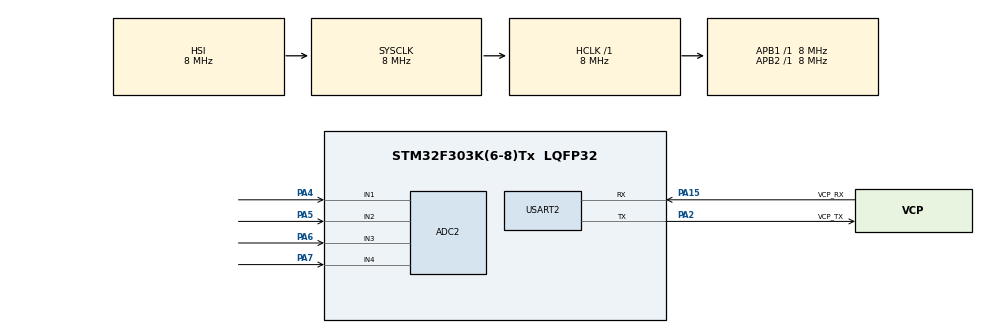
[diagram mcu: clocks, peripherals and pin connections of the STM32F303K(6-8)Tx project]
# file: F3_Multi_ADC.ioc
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ADC2.Channel-0\#ChannelRegularConversion=ADC_CHANNEL_4
ADC2.Channel-1\#ChannelRegularConversion=ADC_CHANNEL_3
ADC2.Channel-2\#ChannelRegularConversion=ADC_CHANNEL_2
ADC2.Channel-3\#ChannelRegularConversion=ADC_CHANNEL_1
ADC2.ClockPrescaler=ADC_CLOCK_SYNC_PCLK_DIV4
ADC2.ContinuousConvMode=ENABLE
ADC2.DMAContinuousRequests=ENABLE
ADC2.EOCSelection=ADC_EOC_SINGLE_CONV
ADC2.NbrOfConversion=4
ADC2.NbrOfConversionFlag=1
ADC2.Offset-0\#ChannelRegularConversion=0
ADC2.Offset-1\#ChannelRegularConversion=0
ADC2.Offset-2\#ChannelRegularConversion=0
ADC2.Offset-3\#ChannelRegularConversion=0
ADC2.OffsetNumber-0\#ChannelRegularConversion=ADC_OFFSET_NONE
ADC2.OffsetNumber-1\#ChannelRegularConversion=ADC_OFFSET_NONE
ADC2.OffsetNumber-2\#ChannelRegularConversion=ADC_OFFSET_NONE
ADC2.OffsetNumber-3\#ChannelRegularConversion=ADC_OFFSET_NONE
ADC2.Rank-0\#ChannelRegularConversion=1
ADC2.Rank-1\#ChannelRegularConversion=2
ADC2.Rank-2\#ChannelRegularConversion=3
ADC2.Rank-3\#ChannelRegularConversion=4
ADC2.SamplingTime-0\#ChannelRegularConversion=ADC_SAMPLETIME_61CYCLES_5
ADC2.SamplingTime-1\#ChannelRegularConversion=ADC_SAMPLETIME_61CYCLES_5
ADC2.SamplingTime-2\#ChannelRegularConversion=ADC_SAMPLETIME_61CYCLES_5
ADC2.SamplingTime-3\#ChannelRegularConversion=ADC_SAMPLETIME_61CYCLES_5
ADC2.SamplingTimeOPAMP-1\#ChannelRegularConversion=ADC_SAMPLETIME_7CYCLES_5
ADC2.SamplingTimeOPAMP-2\#ChannelRegularConversion=ADC_SAMPLETIME_7CYCLES_5
ADC2.SamplingTimeOPAMP-3\#ChannelRegularConversion=ADC_SAMPLETIME_7CYCLES_5
ADC2.SubFamily=STM32F303x8
Dma.ADC2.0.Direction=DMA_PERIPH_TO_MEMORY
Dma.ADC2.0.Instance=DMA1_Channel2
Dma.ADC2.0.MemDataAlignment=DMA_MDATAALIGN_HALFWORD
Dma.ADC2.0.MemInc=DMA_MINC_ENABLE
Dma.ADC2.0.Mode=DMA_CIRCULAR
Dma.ADC2.0.PeriphDataAlignment=DMA_PDATAALIGN_HALFWORD
Dma.ADC2.0.PeriphInc=DMA_PINC_DISABLE
Dma.ADC2.0.Priority=DMA_PRIORITY_LOW
Dma.Request0=ADC2
Mcu.Family=STM32F3
Mcu.Name=STM32F303K(6-8)Tx
Mcu.Package=LQFP32
NVIC.DMA1_Channel2_IRQn=true\:0\:0\:false\:false\:true\:false\:true\:true
NVIC.PriorityGroup=NVIC_PRIORITYGROUP_4
PA13.GPIO_Label=SWDIO
PA13.Mode=Serial_Wire
PA13.Signal=SYS_JTMS-SWDIO
PA14.GPIO_Label=SWCLK
PA14.Mode=Serial_Wire
PA14.Signal=SYS_JTCK-SWCLK
PA15.GPIO_Label=VCP_RX
PA15.Mode=Asynchronous
PA15.Signal=USART2_RX
PA2.GPIO_Label=VCP_TX
PA2.Mode=Asynchronous
PA2.Signal=USART2_TX
PA4.Mode=IN1-Single-Ended
PA4.Signal=ADC2_IN1
PA5.Mode=IN2-Single-Ended
PA5.Signal=ADC2_IN2
PA6.Mode=IN3-Single-Ended
PA6.Signal=ADC2_IN3
PA7.Mode=IN4-Single-Ended
PA7.Signal=ADC2_IN4
PF0\ /\ OSC_IN.GPIO_Label=MCO
PF0\ /\ OSC_IN.Mode=HSE-External-Clock-Source
PF0\ /\ OSC_IN.Signal=RCC_OSC_IN
ProjectManager.HeapSize=0x200
ProjectManager.StackSize=0x400
ProjectManager.TargetToolchain=STM32CubeIDE
RCC.AHBFreq_Value=8000000
RCC.APB1Freq_Value=8000000
RCC.APB2Freq_Value=8000000
RCC.CortexFreq_Value=8000000
RCC.HSE_VALUE=8000000
RCC.HSI_VALUE=8000000
RCC.PLLMUL=RCC_PLL_MUL4
RCC.SYSCLKFreq_VALUE=8000000
USART2.VirtualMode-Asynchronous=VM_ASYNC
board=NUCLEO-F303K8

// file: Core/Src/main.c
/* USER CODE BEGIN Header */
/**
  ******************************************************************************
  * @file           : main.c
  * @brief          : Main program body
  ******************************************************************************
  * @attention
  *
  * Copyright (c) 2024 STMicroelectronics.
  * All rights reserved.
  *
  * This software is licensed under terms that can be found in the LICENSE file
  * in the root directory of this software component.
  * If no LICENSE file comes with this software, it is provided AS-IS.
  *
  ******************************************************************************
  */
/* USER CODE END Header */
#include "main.h"

/* USER CODE BEGIN PD */
uint16_t adcvalue[4];
/* USER CODE END PD */

ADC_HandleTypeDef hadc2;
DMA_HandleTypeDef hdma_adc2;

UART_HandleTypeDef huart2;

void SystemClock_Config(void);
static void MX_GPIO_Init(void);
static void MX_DMA_Init(void);
static void MX_USART2_UART_Init(void);
static void MX_ADC2_Init(void);

int main(void)
{

  /* MCU Configuration--------------------------------------------------------*/

  /* Reset of all peripherals, Initializes the Flash interface and the Systick. */
  HAL_Init();

  /* Configure the system clock */
  SystemClock_Config();

  /* Initialize all configured peripherals */
  MX_GPIO_Init();
  MX_DMA_Init();
  MX_USART2_UART_Init();
  MX_ADC2_Init();
  /* USER CODE BEGIN 2 */
HAL_ADCEx_Calibration_Start(&hadc2,ADC_SINGLE_ENDED);

uint16_t result[16] = {0};

HAL_ADC_Start_DMA(&hadc2,(uint32_t *)&result,4);

//HAL_ADC_PollForConversion(&hadc2,HAL_MAX_DELAY);

//HAL_ADC_Start(&hadc2);

//while(!(ADC2->ISR & (1<<2))){}
//result[0]=HAL_ADC_GetValue(&hadc2);
//
//while(!(ADC2->ISR & (1<<2))){}
//result[1]=HAL_ADC_GetValue(&hadc2);
//
//while(!(ADC2->ISR & (1<<2))){}
//result[2]=HAL_ADC_GetValue(&hadc2);
//
//while(!(ADC2->ISR & (1<<2))){}
//result[3]=HAL_ADC_GetValue(&hadc2);
//
//HAL_ADC_Start(&hadc2);
//
//while(!(ADC2->ISR & (1<<2))){}
//result[4]=HAL_ADC_GetValue(&hadc2);
//
//while(!(ADC2->ISR & (1<<2))){}
//result[5]=HAL_ADC_GetValue(&hadc2);
//
//while(!(ADC2->ISR & (1<<2))){}
//result[6]=HAL_ADC_GetValue(&hadc2);
//
//while(!(ADC2->ISR & (1<<2))){}
//result[7]=HAL_ADC_GetValue(&hadc2);
  /* USER CODE END 2 */

  /* Infinite loop */
  /* USER CODE BEGIN WHILE */
  while (1)
  {
	  for(int i=0;i<8;i++){
		  adcvalue[i]=result[i];
	  }
//	  HAL_Delay(100);
    /* USER CODE END WHILE */

  }
}

void SystemClock_Config(void)
{
  RCC_OscInitTypeDef RCC_OscInitStruct = {0};
  RCC_ClkInitTypeDef RCC_ClkInitStruct = {0};

  /** Initializes the RCC Oscillators according to the specified parameters
  * in the RCC_OscInitTypeDef structure.
  */
  RCC_OscInitStruct.OscillatorType = RCC_OSCILLATORTYPE_HSI;
  RCC_OscInitStruct.HSIState = RCC_HSI_ON;
  RCC_OscInitStruct.HSICalibrationValue = RCC_HSICALIBRATION_DEFAULT;
  RCC_OscInitStruct.PLL.PLLState = RCC_PLL_NONE;
  if (HAL_RCC_OscConfig(&RCC_OscInitStruct) != HAL_OK)
  {
    Error_Handler();
  }

  /** Initializes the CPU, AHB and APB buses clocks
  */
  RCC_ClkInitStruct.ClockType = RCC_CLOCKTYPE_HCLK|RCC_CLOCKTYPE_SYSCLK
                              |RCC_CLOCKTYPE_PCLK1|RCC_CLOCKTYPE_PCLK2;
  RCC_ClkInitStruct.SYSCLKSource = RCC_SYSCLKSOURCE_HSI;
  RCC_ClkInitStruct.AHBCLKDivider = RCC_SYSCLK_DIV1;
  RCC_ClkInitStruct.APB1CLKDivider = RCC_HCLK_DIV1;
  RCC_ClkInitStruct.APB2CLKDivider = RCC_HCLK_DIV1;

  if (HAL_RCC_ClockConfig(&RCC_ClkInitStruct, FLASH_LATENCY_0) != HAL_OK)
  {
    Error_Handler();
  }
}

static void MX_ADC2_Init(void)
{

  ADC_ChannelConfTypeDef sConfig = {0};

  /** Common config
  */
  hadc2.Instance = ADC2;
  hadc2.Init.ClockPrescaler = ADC_CLOCK_SYNC_PCLK_DIV4;
  hadc2.Init.Resolution = ADC_RESOLUTION_12B;
  hadc2.Init.ScanConvMode = ADC_SCAN_ENABLE;
  hadc2.Init.ContinuousConvMode = ENABLE;
  hadc2.Init.DiscontinuousConvMode = DISABLE;
  hadc2.Init.ExternalTrigConvEdge = ADC_EXTERNALTRIGCONVEDGE_NONE;
  hadc2.Init.ExternalTrigConv = ADC_SOFTWARE_START;
  hadc2.Init.DataAlign = ADC_DATAALIGN_RIGHT;
  hadc2.Init.NbrOfConversion = 4;
  hadc2.Init.DMAContinuousRequests = ENABLE;
  hadc2.Init.EOCSelection = ADC_EOC_SINGLE_CONV;
  hadc2.Init.LowPowerAutoWait = DISABLE;
  hadc2.Init.Overrun = ADC_OVR_DATA_OVERWRITTEN;
  if (HAL_ADC_Init(&hadc2) != HAL_OK)
  {
    Error_Handler();
  }

  /** Configure Regular Channel
  */
  sConfig.Channel = ADC_CHANNEL_4;
  sConfig.Rank = ADC_REGULAR_RANK_1;
  sConfig.SingleDiff = ADC_SINGLE_ENDED;
  sConfig.SamplingTime = ADC_SAMPLETIME_61CYCLES_5;
  sConfig.OffsetNumber = ADC_OFFSET_NONE;
  sConfig.Offset = 0;
  if (HAL_ADC_ConfigChannel(&hadc2, &sConfig) != HAL_OK)
  {
    Error_Handler();
  }

  /** Configure Regular Channel
  */
  sConfig.Channel = ADC_CHANNEL_3;
  sConfig.Rank = ADC_REGULAR_RANK_2;
  if (HAL_ADC_ConfigChannel(&hadc2, &sConfig) != HAL_OK)
  {
    Error_Handler();
  }

  /** Configure Regular Channel
  */
  sConfig.Channel = ADC_CHANNEL_2;
  sConfig.Rank = ADC_REGULAR_RANK_3;
  if (HAL_ADC_ConfigChannel(&hadc2, &sConfig) != HAL_OK)
  {
    Error_Handler();
  }

  /** Configure Regular Channel
  */
  sConfig.Channel = ADC_CHANNEL_1;
  sConfig.Rank = ADC_REGULAR_RANK_4;
  if (HAL_ADC_ConfigChannel(&hadc2, &sConfig) != HAL_OK)
  {
    Error_Handler();
  }

}

static void MX_USART2_UART_Init(void)
{

  huart2.Instance = USART2;
  huart2.Init.BaudRate = 38400;
  huart2.Init.WordLength = UART_WORDLENGTH_8B;
  huart2.Init.StopBits = UART_STOPBITS_1;
  huart2.Init.Parity = UART_PARITY_NONE;
  huart2.Init.Mode = UART_MODE_TX_RX;
  huart2.Init.HwFlowCtl = UART_HWCONTROL_NONE;
  huart2.Init.OverSampling = UART_OVERSAMPLING_16;
  huart2.Init.OneBitSampling = UART_ONE_BIT_SAMPLE_DISABLE;
  huart2.AdvancedInit.AdvFeatureInit = UART_ADVFEATURE_NO_INIT;
  if (HAL_UART_Init(&huart2) != HAL_OK)
  {
    Error_Handler();
  }

}

static void MX_DMA_Init(void)
{

  /* DMA controller clock enable */
  __HAL_RCC_DMA1_CLK_ENABLE();

  /* DMA interrupt init */
  /* DMA1_Channel2_IRQn interrupt configuration */
  HAL_NVIC_SetPriority(DMA1_Channel2_IRQn, 0, 0);
  HAL_NVIC_EnableIRQ(DMA1_Channel2_IRQn);

}

static void MX_GPIO_Init(void)
{

  /* GPIO Ports Clock Enable */
  __HAL_RCC_GPIOF_CLK_ENABLE();
  __HAL_RCC_GPIOA_CLK_ENABLE();

}

void Error_Handler(void)
{
  __disable_irq();
  while (1)
  {
  }
}
